# RN821X_RN721X_SOC_V2 register map
File version: v1.0.7
CPU: CM0 r0p0, little endian, no MPU, no FPU, 3 interrupt priority bits
Registers are 32-bit, read-write, reset 0x0 unless marked. A register's access mark holds for its fields unless they carry their own. Offsets are from the block's base; [hi:lo] are bit positions; 'fields as' and 'values as' point back to an identical list.

## EMU — energy metering unit
Base 0x50004000
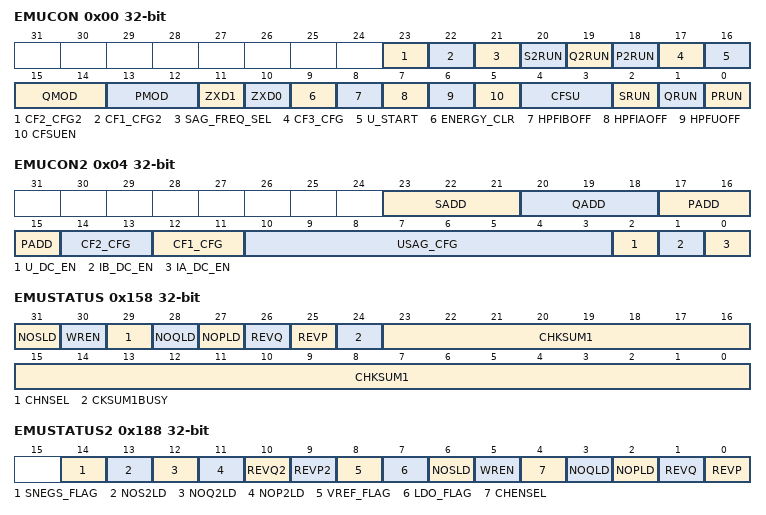
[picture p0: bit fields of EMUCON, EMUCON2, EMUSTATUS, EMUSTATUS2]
0x00 EMUCON — Control
  [23] CF2_CFG2 — QF pad configuration(with EMUCON2.CF2_CFG)
  [22] CF1_CFG2 — PF pad configuration(with EMUCON2.CF1_CFG)
  [21] SAG_FREQ_SEL — sag frequency selector
  [20] S2RUN — enable apparent power register 2 accumulate
    0=DIS (disable apparent power register 2 accumulate); 1=EN (enable apparent power register 2 accumulate)
  [19] Q2RUN — enable reactive power register 2 accumulate
    0=DIS (disable reactive power register 2 accumulate); 1=EN (enable reactive power register 2 accumulate)
  [18] P2RUN — enable active power register 2 accumulate
    0=DIS (disable active power register 2 accumulate); 1=EN (enable active power register 2 accumulate)
  [17] CF3_CFG — PIN SF redefine
    0=SF1 (redefine SF as SF1); 1=SF2 (redefine SF as SF2)
  [16] U_START — apparent power U-channel selection
    0=DIS (count U-channel when calculate apparent power); 1=EN (ignore U-channel when calculate apparent power)
  [15:14] QMOD — reactive power accumulation mode
    0=POSNEG (accumulating both positive and negative power,keeping sign to negative power); 1=POS (accumulating only positive); 2=ABS (accumulating absolute value of both positive and negative power); 3=NEG (do not use)
  [13:12] PMOD — active power accumulation mode
    values as QMOD
  [11] ZXD1 — ZX output mode
    0=DIS (toggle ZX only at zero crossing point defined by ZXD0); 1=EN (toggle ZX only at both positive and negative zero crossing point)
  [10] ZXD0 — zero-crossing point selection
    0=POS (select positive zero-crossing point); 1=NEG (select negative zero-crossing point)
  [9] ENERGY_CLR — all register clear as 0 after reading
    0=CLEAR (all register clear as 0 after reading); 1=HOLD (all register hold on after reading)
  [8] HPFIBOFF — IB-channel digital high-pass filters enable
    0=EN (enable DHPF in IB-channel); 1=DIS (disable DHPF in IB-channel)
  [7] HPFIAOFF — IA-channel digital high-pass filters enable
    0=EN (enable DHPF in IA-channel); 1=DIS (disable DHPF in IA-channel)
  [6] HPFUOFF — U-channel digital high-pass filters enable
    0=EN (enable DHPF in U-channel); 1=DIS (disable DHPF in U-channel)
  [5] CFSUEN — PF/QF output acceleration enable
    0=DIS (PF/QF output rate set as normal); 1=EN (accelerating PF/QF output rate defined as CFSU)
  [4:3] CFSU — PF/QF output acceleration rate
    0=PF/QF output rate accelerated at x2; 1=PF/QF output rate accelerated at x4; 2=PF/QF output rate accelerated at x8; 3=PF/QF output rate accelerated at x16
  [2] SRUN — reactive power accumulation and SF pulse output
    0=DIS (stop accumulating reactive power and outputing SF pulse); 1=EN (start accumulating reactive power and outputing SF pulse)
  [1] QRUN — reactive power accumulation and QF pulse output
    0=DIS (stop accumulating reactive power and outputing QF pulse); 1=EN (start accumulating reactive power and outputing QF pulse)
  [0] PRUN — active power accumulation and PF pulse output
    0=DIS (stop accumulating active power and outputing PF pulse); 1=EN (start accumulating active power and outputing PF pulse)
0x04 EMUCON2 — Control2
  [23:21] SADD — SF addition mode
    0=P0 (SA or SB); 1=P1 (SB); 2=P2 (QB); 3=P3 (user define); 4=P4 (+SA+SB); 5=P5 (+SA-SB); 6=P6 (-SA+SB); 7=P7 (-SA-SB)
  [20:18] QADD — QF addition mode
    0=P0 (QA or QB); 1=P1 (PA); 2=P2 (PB); 3=P3 (|QA|+|QB|); 4=P4 (+QA+QB); 5=P5 (+QA-QB); 6=P6 (-QA+QB); 7=P7 (-QA-QB)
  [17:15] PADD — PF addition mode
    0=P0 (PA); 1=P1 (PA); 2=P2 (PB); 3=P3 (|PA|+|PB|); 4=P4 (+PA+PB); 5=P5 (+PA-PB); 6=P6 (-PA+PB); 7=P7 (-PA-PB)
  [14:13] CF2_CFG — QF pin switch over config
  [12:11] CF1_CFG — PF pin switch over config
  [10:3] USAG_CFG — voltage sag half cycle count
  [2] U_DC_EN — U channel DC offset enable
    0=DIS (disable U channel DC offset correction); 1=EN (enable U channel DC offset correction)
  [1] IB_DC_EN — IB channel DC offset enable
    0=DIS (disable IB channel DC offset correction); 1=EN (enable IB channel DC offset correction)
  [0] IA_DC_EN — IA channel DC offset enable
    0=DIS (disable IA channel DC offset correction); 1=EN (enable IA channel DC offset correction)
0x08 HFCONST — high frequency impulse constant
  [15:0] HFCONST — high frequency impulse constant bits
0x0C PSTART — active power starting threshold
  [15:0] PSTART — active power starting threshold bits
0x10 QSTART — reactive power starting threshold
  [15:0] QSTART — reactive power starting threshold bits
0x14 GPQA — IA Channel power gain,used for active(reactive) power gain calibration of IA Channel and U channel
  [15:0] GPQA — IA Channel power gain,used for active(reactive) power gain calibration of IA Channel and U channel bits
0x18 GPQB — IB Channel power gain,used for active(reactive) power gain calibration of IB Channel and U channel
  [15:0] GPQB — IB Channel power gain,used for active(reactive) power gain calibration of IB Channel and U channel bits
0x1C PHSA — phase adjustment for IA Channel and U channel
  [8:0] PHSA
0x20 PHSB — phase adjustment for IB Channel and U channel
  [8:0] PHSB
0x24 QPHSCAL — reactive power phase Calibration
  [15:0] QPHSCAL
0x28 APOSA — IA channel active power offset
  [15:0] APOSA
0x2C APOSB — IB channel active power offset
  [15:0] APOSB — IA channel reactive power offset calibration
0x30 RPOSA — IA channel reactive power offset calibration
  [15:0] RPOSA — IB channel reactive power offset calibration
0x34 RPOSB — IB channel reactive power offset calibration
  [15:0] RPOSB
0x38 IARMSOS — IA channel RMS offset calibration
  [15:0] IARMSOS
0x3C IBRMSOS — IB channel RMS offset calibration
  [15:0] IBRMSOS
0x40 URMSOS — U channel RMS offset calibration
  [15:0] URMSOS
0x44 IAGAIN — IA channel gain for channel coherence calibration
  [15:0] IAGAIN
0x48 IBGAIN — IB channel gain for channel coherence calibration
  [15:0] IBGAIN
0x4C UGAIN — U channel gain for channel coherence calibration
  [15:0] UGAIN
0x50 IADCOS — IA channel direct current offset calibration
  [23:0] IADCOS
0x54 IBDCOS — IB channel direct current offset calibration
  [23:0] IBDCOS
0x58 UDCOS — U channel direct current offset calibration
  [23:0] UDCOS
0x5C UADD — U channel bias
  [23:0] UADD
0x60 USAG — U channel sag threshold
  [15:0] USAG
0x64 IAPEAK — IA channel peak detection threshold
  [15:0] IAPEAK
0x68 IBPEAK — IB channel peak detection threshold
  [15:0] IBPEAK
0x6C UPEAK — U channel peak detection threshold
  [15:0] UPEAK
0x70 D2FP — User-defined Power Register
0x74 EMUCON3 — Control3
  [17:0] EMUCON3
0x78 EMUCON4 — Control4
  [15:0] EMUCON4
0x7C EMUCON5 — Control5
  [11:0] EMUCON5
0x80 CF_CFG — CF configuration
  [19:0] CF_CFG
0x84 HWRMS_CFG — half-wave rms configuration
  [14:0] HWRMS_CFG
0x88 HWP_CFG — half-wave power configuration
  [13:0] HWP_CFG
0x8C HWFP_CFG — half-wave fundamental power configuration
  [12:0] HWFP_CFG
0x90 HWQ_CFG — half-wave reactive power configuration
  [14:0] HWQ_CFG
0x94 HFCONST2 — high frequency impulse constant2
  [15:0] HFCONST2
0x98 HFCONST3 — high frequency impulse constant3
  [15:0] HFCONST3
0x9C NEG1BIT_EN — one-bit input invert configuration
0xA0 EMUMODE — EMU mode configuration
0xA4 ATCHOP_CFG — auto chop configuration
  [9:0] ATCHOP_CFG
0xA8 FGAIN — fundamental gain for channel coherence calibration
  [15:0] FGAIN
0xAC APOSFA — IA channel fundamental active power offset
  [15:0] APOSFA
0xB0 APOSFB — IB channel fundamental active power offset
  [15:0] APOSFB
0xB4 IAHWRMSOS — IA channel half-wave rms offset calibration
  [15:0] IAHWRMSOS
0xB8 IBHWRMSOS — IB channel half-wave rms offset calibration
  [15:0] IBHWRMSOS
0xBC UHWRMSOS — U channel half-wave rms offset calibration
  [15:0] UHWRMSOS
0xC0 PF2CNT — active power counter
  [15:0] PF2CNT
0xC4 QF2CNT — reactive power counter
  [15:0] QF2CNT
0xC8 SF2CNT — apparent power counter
  [15:0] SF2CNT
0xE0 PF2CNT2 — IB active power counter2
  [15:0] PF2CNT2
0xE4 QF2CNT2 — IB reactive power counter2
  [15:0] QF2CNT2
0xE8 PF2CNT3 — IB active power counter3
  [15:0] PF2CNT3
0xEC QF2CNT3 — IB reactive power counter3
  [15:0] QF2CNT3
0xF0 PFCNT2 — IA active power counter2
  [15:0] PFCNT2
0xF4 QFCNT2 — IA reactive power counter2
  [15:0] QFCNT2
0xF8 PFCNT3 — IA active power counter3
  [15:0] PFCNT3
0xFC QFCNT3 — IA reactive power counter3
  [15:0] QFCNT3
0x100 PFCNT — active power counter
  [15:0] PFCNT
0x104 QFCNT — reactive power counter
  [15:0] QFCNT
0x108 SFCNT — apparent power counter
  [15:0] SFCNT
0x10C IARMS ro
  [23:0] IARMS
0x110 IBRMS ro
  [23:0] IBRMS
0x114 URMS ro
  [23:0] URMS
0x118 UFREQ ro — voltage frequency
  [15:0] UFREQ
0x11C POWERPA ro — active power in binary complement format,with MSB as sign,which is average active power of IA and U channel
0x120 POWERPB ro — active power in binary complement format,with MSB as sign,which is average active power of IB and U channel
0x124 POWERQA ro — reactive power in binary complement format,with MSB as sign,which is average reactive power of IA and U channel
0x128 POWERQB ro — reactive power in binary complement format,with MSB as sign,which is average reactive power of IB and U channel
0x12C POWERSA ro — apparent power in binary complement format,with MSB as sign,which is average apparent power of IA and U channel
0x130 POWERSB ro — apparent power in binary complement format,with MSB as sign,which is average apparent power of IB and U channel
0x134 ENERGYP ro — active energy
  [23:0] ENERGYP
0x138 ENERGYP2 ro — active energy2
  [23:0] ENERGYP2
0x13C ENERGYQ ro — reactive energy
  [23:0] ENERGYQ
0x140 ENERGYQ2 ro — reactive energy2
  [23:0] ENERGYQ2
0x144 ENERGYS ro — apperant energy
  [23:0] ENERGYS
0x148 PFA ro — IA channel power factor
  [23:0] PFA
0x14C PFB ro — IB channel power factor
  [23:0] PFB
0x150 ANGLEA ro — angle of IA and U channel
  [15:0] ANGLEA — angel of IA and U channel
0x154 ANGLEB ro — angle of IB and U channel
  [15:0] ANGLEB — angel of IB and U channel
0x158 EMUSTATUS ro — status
  [31] NOSLD — Apparent power and start-up power status register
    0=NOSLD (when apparent power is more than or equal start-up power ,NoSld is 0.); 1=SLD (when apparent power is less than start-up power ,NoSld is set to 1.)
  [30] WREN — write enable
    0=DIS (disable write to protected registers); 1=EN (enable write to protected registers)
  [29] CHNSEL — current channel selection
    0=A (IA channel used to calculate active(reactive) power); 1=B (IB channel used to calculate active(reactive) power)
  [28] NOQLD — reactive power too small flag
    0=BIG (reactive power greater than or equal with starting power); 1=SMALL (reactive power less than starting power)
  [27] NOPLD — active power too small flag
    0=BIG (active power greater than or equal with starting power); 1=SMALL (active power less than starting power)
  [26] REVQ — indication reactive power reversion
    0=POS (reactive power change from negative to postive); 1=NEG (reactive power change from postive to negative)
  [25] REVP — indication active power reversion
    0=POS (active power change from negative to postive); 1=NEG (active power change from postive to negative)
  [24] CKSUM1BUSY — checksum calculation
    0=DONE (calibration data checksum calculation has been completed); 1=BUSY (calibration data checksum during calculation)
  [23:0] CHKSUM1 — checksum of all meter parameter registers
0x15C SPL_IA ro — sample value of current channel A ,for whick refresh rate is 7.2KHz.
  [23:0] SPL_IA
0x160 SPL_IB ro — sample value of current channel B ,whose refresh rate is 7.2KHz.
  [23:0] SPL_IB
0x164 SPL_U ro — sample value of voltage channel ,for whick refresh rate is 7.2KHz.
  [23:0] SPL_U
0x168 POWERPA2 ro — Active power A,whose refresh rate is 13.67Hz and stabilization time is about 300ms.
0x16C POWERPB2 ro — Active power B,whose refresh rate is 13.67Hz and stabilization time is about 300ms.
0x170 ENERGYS2 ro — Apparent Energy of channel 2, which can be configured as clear-after-read or not-clear-after-read.Default is clear-after-read.
  [23:0] ENERGYS2
0x174 SPL_PA ro — instantaneous active power of channel A, whose refresh rate is 7.2KHz.
0x178 SPL_PB ro — instantaneous active power of channel B, whose refresh rate is 7.2KHz.
0x17C SPL_QA ro — instantaneous reactive power of channel A, whose refresh rate is 7.2KHz.
0x180 SPL_QB ro — instantaneous reactive power of channel B, whose refresh rate is 7.2KHz.
0x188 EMUSTATUS2 ro — status
  [14] SNEGS_FLAG — adc input reverse flag
    0=postive adc input; 1=negative adc input
  [13] NOS2LD — apparent power and starting power status register
    0=When apparent power 2 is more than or equal to starting power ,Nosld is clear to 0; 1=when apparent power 2 is less than starting power ,Nosld is set to 1
  [12] NOQ2LD — reactive power and starting power status register
    0=When reactive power 2 is more than or equal to starting power ,Nopld is clear to 0; 1=when reactive power 2 is less than starting power ,Nopld is set to 1
  [11] NOP2LD — active power 2 and starting power status register
    0=When active power 2 is more than or equal to starting power ,Nopld is clear to 0; 1=when active power 2 is less than starting power ,Nopld is set to 1
  [10] REVQ2 — indication of reverse reactive power 2.
    0=when the next detecting result is positive reactive power ,clear the bit as 0; 1=when negative reactive power is detected ,set the bit as 1
  [9] REVP2 — indication of reverse active power 2.
    0=when the next detecting result is positive active power ,clear the bit as 0 ; 1=when negative active power is detected ,set the bit as 1
  [8] VREF_FLAG — indicaion of Vref.
    0=0:Vref value is less than threshold voltage; 1=1:Vref is normal
  [7] LDO_FLAG — indicaion of LDO.
    0=0:LDO value is less than threshold voltage; 1=1:LDO is normal
  [6] NOSLD — apparent power adn starting power status register
    0=When apparent power is more than or equal to starting power ,Nosld is clear to 0; 1=when apparent power is less than starting power ,Nosld is set to 1
  [5] WREN — write enable flag.
    0=0:disable to write the protected register; 1=1:enable to write the protected register
  [4] CHENSEL — indicaion of selected current channel.Default is 0.
    0=0:the current channel for caculating active/reactive energy is A; 1=1:the current channel for caculating active/reactive energy is B
  [3] NOQLD — reactive power and starting power status register
    0=When reactive power is more than or equal to starting power ,Noqld is clear to 0; 1=when reactive power is less than starting power ,Noqld is set to 1
  [2] NOPLD — active power and starting power status register
    0=When active power is more than or equal to starting power ,Nopld is clear to 0; 1=when active power is less than starting power ,Nopld is set to 1
  [1] REVQ — indication of reverse reactive power
    0=when the next detecting result is positive reactive power ,clear the bit as 0 ; 1=when negative reactive power is detected ,set the bit as 1
  [0] REVP — indication of reverse active power.
    values as REVP2
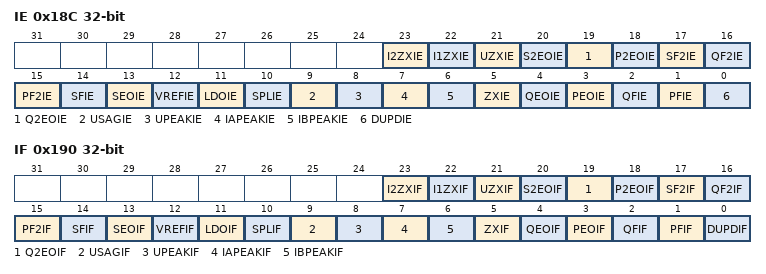
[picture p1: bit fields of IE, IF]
0x18C IE — interrupt enable
  [23] I2ZXIE
    0=DIS (disable zero-crossing interrupt of current channel 2); 1=EN (enable zero-crossing interrupt of current channel 2)
  [22] I1ZXIE
    0=DIS (disable zero-crossing interrupt of current channel 1); 1=EN (enable zero-crossing interrupt of current channel 1)
  [21] UZXIE — I1ZXIE
    0=DIS (disable zero-crossing interrupt of voltage channel); 1=EN (enable zero-crossing interrupt of voltage channel)
  [20] S2EOIE
    0=DIS (disable overflow interrupt of apparent energy register); 1=EN (enable overflow interrupt of apparent energy registe)
  [19] Q2EOIE
    0=DIS (disable overflow interrupt of reactive energy register); 1=EN (enable overflow interrupt of reactive energy registe)
  [18] P2EOIE
    0=DIS (disable overflow interrupt of active energy register); 1=EN (enable overflow interrupt of active energy registe)
  [17] SF2IE — SFIE
    0=DIS (disable SF2 interrupt); 1=EN (enable SF2 interrupt)
  [16] QF2IE — SFIE
    0=DIS (disable QF2 interrupt); 1=EN (enable QF2 interrupt)
  [15] PF2IE — SFIE
    0=DIS (disable PF2 interrupt); 1=EN (enable PF2 interrupt)
  [14] SFIE
    0=CLOSE (colse SF interrupt); 1=OPEN (open SF interrupt)
  [13] SEOIE — apperant energy overflow interrupt enable
    0=DIS (do not generate interrupt request on apperant energy overflow event); 1=EN (generate interrupt request on apperant energy overflow event)
  [12] VREFIE — VREF reset interrupt enable
    0=DIS (do not generate interrupt request on VREF reset event); 1=EN (generate interrupt request on VREF reset event)
  [11] LDOIE — LDO reset interrupt enable
    0=DIS (do not generate interrupt request on LDO reset event); 1=EN (generate interrupt request on LDO reset event)
  [10] SPLIE — ADC sampling interrupt enable
    0=DIS (do not generate interrupt request on ADC sampling event); 1=EN (generate interrupt request on ADC sampling event)
  [9] USAGIE — U channel sag interrupt enable
    0=DIS (do not generate interrupt request on U channel sag event); 1=EN (generate interrupt request on U channel sag event)
  [8] UPEAKIE — U channel overload interrupt enable
    0=DIS (do not generate interrupt request on U channel overload event); 1=EN (generate interrupt request on U channel overload event)
  [7] IAPEAKIE — IA channel overload interrupt enable
    0=DIS (do not generate interrupt request on IA channel overload event); 1=EN (generate interrupt request on IA channel overload event)
  [6] IBPEAKIE — IB channel overload interrupt enable
    0=DIS (do not generate interrupt request on IB channel overload event); 1=EN (generate interrupt request on IB channel overload event)
  [5] ZXIE — zero crossing interrupt enable
    0=DIS (do not generate interrupt request on zero crossing event); 1=EN (generate interrupt request on zero crossing event)
  [4] QEOIE — reactive energy overflow interrupt enable
    0=DIS (do not generate interrupt request on reactive energy overflow event); 1=EN (generate interrupt request on active reenergy overflow event)
  [3] PEOIE — active energy overflow interrupt enable
    0=DIS (do not generate interrupt request on active energy overflow event); 1=EN (generate interrupt request on active energy overflow event)
  [2] QFIE — QF interrupt enable
    0=DIS (do not generate interrupt request on QF event); 1=EN (generate interrupt request on QF event)
  [1] PFIE — PF interrupt enable
    0=DIS (do not generate interrupt request on PF event); 1=EN (generate interrupt request on PF event)
  [0] DUPDIE — data update interrupt enable
    0=DIS (do not generate interrupt request when update found on PowerPA,PowerPB,PowerQ,IARMS,IBRMS and URMS); 1=EN (generate interrupt request when update found on PowerPA,PowerPB,PowerQ,IARMS,IBRMS and URMS)
0x190 IF — interrupt flag
  [23] I2ZXIF — zero-crossing interrupt flag
    0=NUL (zero-crossing interrupt of current channel 2 didn't occur.); 1=OCC (zero-crossing interrupt of current channel 2 occured.)
  [22] I1ZXIF — zero-crossing interrupt flag
    0=NUL (zero-crossing interrupt of current channel 1 didn't occur.); 1=OCC (zero-crossing interrupt of current channel 1 occured.)
  [21] UZXIF — zero-crossing interrupt flag
    0=NUL (zero-crossing interrupt of voltage channel didn't occur.); 1=OCC (zero-crossing interrupt of voltage channel occured.)
  [20] S2EOIF — overflow flag
    0=NUL (apparent energy register 2 isn't overflow); 1=OCC (apparent energy register 2 is overflow)
  [19] Q2EOIF — overflow flag
    0=NUL (reactive energy register 2 isn't overflow); 1=OCC (reactive energy register 2 overflow)
  [18] P2EOIF — overflow flag
    0=NUL (active energy register 2 isn't overflow); 1=OCC (active energy register 2 overflow)
  [17] SF2IF — SF2 pulse output flag
    0=NUL (no pending SF2 event); 1=OCC (found pending SF2 event)
  [16] QF2IF — SF pulse output flag
    0=NUL (no pending QF2 event); 1=OCC (found pending QF2 event)
  [15] PF2IF — apperant energy overflow interrupt flag
    0=NUL (no pending SF event); 1=OCC (found pending SF event)
  [14] SFIF — SF interrupt flag
    0=NUL (no pending SF event); 1=OCC (found pending SF event)
  [13] SEOIF — apparent energy interrupt flag
    0=NUL (no pending apparent energy overflow); 1=OCC (found pending apparent energy overflow)
  [12] VREFIF — VREF reset interrupt flag
    0=NUL (no pending VREF reset event); 1=OCC (found pending VREF reset event)
  [11] LDOIF — LDO reset interrupt flag
    0=NUL (no pending LDO reset event); 1=OCC (found pending LDO reset event)
  [10] SPLIF — ADC sampling interrupt flag
    0=NUL (no pending ADC sampling event); 1=OCC (found pending ADC sampling event)
  [9] USAGIF — U channel sag interrupt flag
    0=NUL (no pending U channel sag event); 1=OCC (found pending U channel sag event)
  [8] UPEAKIF — U channel overload interrupt flag
    0=NUL (no pending U channel overload event); 1=OCC (found pending U channel overload event)
  [7] IAPEAKIF — IA channel overload interrupt flag
    0=NUL (no pending IA channel overload event); 1=OCC (found pending IA channel overload event)
  [6] IBPEAKIF — IB channel overload interrupt flag
    0=NUL (no pending IB channel overload event); 1=OCC (found pending IB channel overload event)
  [5] ZXIF — zero crossing interrupt flag
    0=NUL (no pending zero crossing event); 1=OCC (found pending zero crossing event)
  [4] QEOIF — reactive energy overflow interrupt flag
    0=NUL (no pending reactive energy overflow event); 1=OCC (found pending active reenergy overflow event)
  [3] PEOIF — active energy overflow interrupt flag
    0=NUL (no pending active energy overflow event); 1=OCC (found pending active energy overflow event)
  [2] QFIF — QF interrupt flag
    0=NUL (no pending QF event); 1=OCC (found pending QF event)
  [1] PFIF — PF interrupt flag
    0=NUL (no pending PF event); 1=OCC (found pending PF event)
  [0] DUPDIF — data update interrupt flag
    0=NUL (not any update found on PowerPA,PowerPB,PowerQ,IARMS,IBRMS and URMS); 1=OCC (update found on PowerPA,PowerPB,PowerQ,IARMS,IBRMS and URMS)
0x194 DMAEN — DMA enable
  [0] DMAEN
0x198 RDATA ro — last read data
0x19C WDATA ro — last written data
0x1A0 IE2 — interrupt2 enable
  [15:0] IE2
0x1A4 IF2 ro — interrupt2 flag
  [15:0] IF2
0x1A8 SPCMD — Special Function Register
  [7:0] SPCMD — Only as the value is 0xe5 ,the EMU register can be written.Only as the value is 0xdc ,the EMU register can not be written.Only when the value is 0x5a ,channel A is set to calculate energy.Only the value is 0xa5 ,channel B is set to calculate energy.
0x1AC EMUSTATUS3 ro — EMU status register3
  [24:0] EMUSTATUS3
0x1B0 IE3 — interrupt3 enable
  [8:0] IE3
0x1B4 IF3 — interrupt3 flag
  [8:0] IF3
0x200 HW_RMSIA ro — IA channel fundamental rms for half-wave updates
  [23:0] HW_RMSIA
0x204 HW_RMSIB ro — IB channel fundamental rms for half-wave updates
  [23:0] HW_RMSIB
0x208 HW_RMSU ro — U channel fundamental rms for half-wave updates
  [23:0] HW_RMSU
0x20C HW_FPA ro — IA channel fundamental active power for half-wave updates
0x210 HW_FPB ro — IB channel fundamental active power for half-wave updates
0x214 SPL_IA2 ro — sample value of current channel A before HPF ,for whick refresh rate is 14.4KHz.
  [23:0] SPL_IA2
0x218 SPL_IB2 ro — sample value of current channel B before HPF ,for whick refresh rate is 14.4KHz.
  [23:0] SPL_IB2
0x21C SPL_U2 ro — sample value of current channel U before HPF ,for whick refresh rate is 7.2KHz.
  [23:0] SPL_U2
0x22C SPL_FIA ro — sample value of current channel A fundamental before HPF ,for whick refresh rate is 7.2KHz.
  [23:0] SPL_FIA
0x230 SPL_FIB ro — sample value of current channel B fundamental before HPF ,for whick refresh rate is 7.2KHz.
  [23:0] SPL_FIB
0x234 SPL_FU ro — sample value of current channel U fundamental before HPF ,for whick refresh rate is 7.2KHz.
  [23:0] SPL_FU
0x238 ENERGYP_2 ro — A active energy register2
  [23:0] ENERGYP_2
0x23C ENERGYP2_2 ro — B active energy register2
  [23:0] ENERGYP2_2
0x240 ENERGYQ_2 ro — A reactive energy register2
  [23:0] ENERGYQ_2
0x244 ENERGYQ2_2 ro — B reactive energy register2
  [23:0] ENERGYQ2_2
0x248 ENERGYP_3 ro — A active energy register3
  [23:0] ENERGYP_3
0x24C ENERGYP2_3 ro — B active energy register3
  [23:0] ENERGYP2_3
0x250 ENERGYQ_3 ro — A reactive energy register3
  [23:0] ENERGYQ_3
0x254 ENERGYQ2_3 ro — B reactive energy register3
  [23:0] ENERGYQ2_3
0x258 IADCOS_CALC ro — IA channel auto direct current offset calibration
  [23:0] IADCOS_CALC
0x25C IBDCOS_CALC ro — IB channel auto direct current offset calibration
  [23:0] IBDCOS_CALC
0x260 UDCOS_CALC ro — U channel auto direct current offset calibration
  [23:0] UDCOS_CALC
0x300 ZXOTCFG — zero crossing configuration
  [4:0] ZXOTCFG
0x304 ZXOTI — I channel zero crossing configuration
  [15:0] ZXOTI
0x308 ZXOTU — U channel zero crossing configuration
  [15:0] ZXOTU
0x30C ROS_CTRL — ROS configuration
  [1:0] ROS_CTRL
0x310 ROS_DCATTC — ROS attenuation coefficient configuration
  [15:0] ROS_DCATTC
0x314 ROS_TRAN_K — ROS transfer coefficient configuration
  [15:0] ROS_TRAN_K
0x318 PQSRUN — power accumulation configuration
  [23:0] PQSRUN
0x330 ECT_EN — ECT enable
0x334 ECT_IAGAIN — IA channel ECT gain
  [15:0] ECT_IAGAIN
0x338 ECT_IBGAIN — IB channel ECT gain
  [15:0] ECT_IBGAIN
0x33C ECT_UGAIN — U channel ECT gain
  [15:0] ECT_UGAIN
0x400 DMA_WAVE_CFG — dma wave configuration
  [14:0] DMA_WAVE_CFG
0x404 DMA_BUF_CTRL — dma buffer configuration
  [0] DMA_BUF_CTRL
0x408 DMA_BUF_BADDR — dma buffer base address configuration
  [14:0] DMA_BUF_BADDR
0x40C DMA_BUF_DEPTH — dma buffer depth configuration
  [14:0] DMA_BUF_DEPTH
0x410 DMA_GAP_CFG — dma gap configuration
  [17:0] DMA_GAP_CFG
0x414 DMA_BUFF_ADDR ro — dma buffer current address
  [13:0] DMA_BUFF_ADDR
0x418 DMA_ERR_ADDR ro — dma buffer error address
  [13:0] DMA_ERR_ADDR
0x41C DMA_CHECKSUM ro
0x420 DMA_RCD_CFG — dma RCD configuration
  [13:0] DMA_RCD_CFG
0x424 DMA_BUF_RCD_CTRL — dma buffer RCD configuration
  [0] DMA_BUF_RCD_CTRL
0x428 DMA_BUF_RCD_BADDR — dma buffer RCD base address configuration
  [14:0] DMA_BUF_RCD_BADDR
0x42C DMA_BUF_RCD_DEPTH — dma buffer RCD depth configuration
  [8:0] DMA_BUF_RCD_DEPTH
0x430 DMA_RCD_GAP_DEPTH ro — dma gap RCD configuration
  [14:0] DMA_RCD_GAP_DEPTH
0x434 DMA_BUF_RCD_ADDR ro — dma buffer RCD current address
  [14:0] DMA_BUF_RCD_ADDR
0x438 DMA_BUF_RCD_ERR_ADDR — dma buffer RCD error address
  [14:0] DMA_BUF_RCD_ERR_ADDR
0x480 RCD_CTRL — RCD configuration
  [19:0] RCD_CTRL
0x484 RCD_EN — RCD enable
  [0] RCD_EN
0x488 RCD_ISTH — RCD input threshold configuration
0x48C RCD_INTCFGA — RCD A threshold configuration
0x490 RCD_INTCFGB — RCD B threshold configuration
  [7:0] RCD_INTCFGB
0x494 RCD_INTRESA — RCD A result configuration
  [15:0] RCD_INTRESA
0x498 RCD_INTRESB — RCD B result configuration
  [7:0] RCD_INTRESB
0x49C RCD_IE — RCD interrupt enable
  [3:0] RCD_IE
0x4A0 RCD_IF — RCD interrupt status
  [3:0] RCD_IF
0x4A4 RCD_STA — RCD status
  [3:0] RCD_STA
0x4B0 TRIG_CTRL — TRIG configuration
  [5:0] TRIG_CTRL
0x4B4 TIRG_EN — TRIG enable
  [0] TIRG_EN
0x4B8 TRIG_STOP
  [1:0] TRIG_STOP
0x4BC TRIG_LEN — TRIG length
  [17:0] TRIG_LEN
0x4C0 TRIG_DLY — TRIG delay
  [15:0] TRIG_DLY
0x4C4 TRIG_STA — TRIG status
  [21:0] TRIG_STA
0x4C8 TRIG_LEN2 — TRIG length2
  [17:0] TRIG_LEN2
0x4CC TRIG_STA2 — TRIG status2
  [21:0] TRIG_STA2
